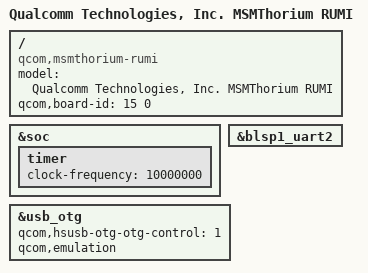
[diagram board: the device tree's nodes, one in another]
/*
 * Copyright (c) 2015, The Linux Foundation. All rights reserved.
 *
 * This program is free software; you can redistribute it and/or modify
 * it under the terms of the GNU General Public License version 2 and
 * only version 2 as published by the Free Software Foundation.
 *
 * This program is distributed in the hope that it will be useful,
 * but WITHOUT ANY WARRANTY; without even the implied warranty of
 * MERCHANTABILITY or FITNESS FOR A PARTICULAR PURPOSE.  See the
 * GNU General Public License for more details.
 */

/dts-v1/;

#include "msmthorium.dtsi"

/ {
	model = "Qualcomm Technologies, Inc. MSMThorium RUMI";
	compatible = "qcom,msmthorium-rumi", "qcom,msmthorium", "qcom,rumi";
	qcom,board-id= <15 0>;
};

&soc {
	timer {
		clock-frequency = <10000000>;
	};
};

&blsp1_uart2 {
	status = "ok";
};

&usb_otg {
	qcom,hsusb-otg-otg-control = <1>;
	qcom,emulation;
};
